# ATA6286 device description
Architecture: AVR8; Family: megaAVR
Registers are 8-bit, access not given, no defined reset value unless marked. A register's access mark holds for its fields unless they carry their own. Offsets are from the block's base; [hi:lo] are bit positions.

## LFRX
Instances: LFRX 0x00
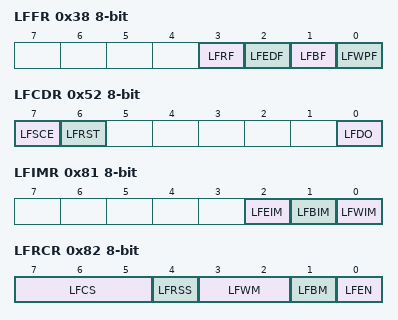
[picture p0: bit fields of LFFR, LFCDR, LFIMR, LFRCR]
0x38 LFFR — Low Frequency Flag Register
  [3] LFRF — LF receiver Rssi data Flag
  [2] LFEDF — LF receiver End of data Flag
  [1] LFBF — LF receiver data Buffer full Flag
  [0] LFWPF — LF receiver Wake-up Flag
0x50 LFRR bits used 6:0 — LF RSSI Data Register
0x52 LFCDR — LF receiver Control und Data Register
  [7] LFSCE — LF receiver RSSI Software Capture Enable Bit
  [6] LFRST — LF receiver Reset Bit
  [0] LFDO — LF receiver Data Output Bit
0x56 LFRB — Low Frequency Receive data Buffer
0x81 LFIMR — Low Frequency Interrupt Mask Register
  [2] LFEIM — LF receiver End of data Interrupt Mask bit
  [1] LFBIM — LF receiver data Buffer Interrupt Mask bit
  [0] LFWIM — LF receiver Wake-up Interrupt Mask bit
0x82 LFRCR — Low Frequency Receiver Control Register
  [7:5] LFCS — LF receiver Capacitor Select Bits
  [4] LFRSS — LF Receiver Sensitivity Select Bit
  [3:2] LFWM — LF receiver Wake-up Mode Bits
  [1] LFBM — LF receiver Burst Mode enable Bit
  [0] LFEN — LF receiver Enable Bit
0x83 LFHCR bits used 6:0 — LF Header Compare Register
0x84 LFIDC 16-bit — LF ID Compare Register
0x86 LFCAL 16-bit — LF Calibration Register Bytes

## EXTERNAL_INTERRUPT
Instances: EXTERNAL_INTERRUPT 0x00
0x37 PCIFR — Pin Change Interrupt Flag Register
  [2:0] PCIF — Pin Change Interrupt Flags
0x3D EIFR — External Interrupt Flag Register
  [1:0] INTF — External Interrupt Flags
0x43 PCICR — Pin Change Interrupt Control Register
  [2:0] PCIE — Pin Change Interrupt Enables
0x44 EIMSK — External Interrupt Mask Register
  [1:0] INT — External Interrupt Request 1 Enable
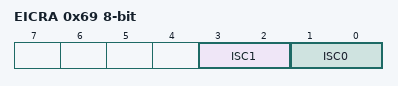
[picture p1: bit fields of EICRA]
0x69 EICRA — External Interrupt Control Register
  [3:2] ISC1 — External Interrupt Sense Control 1 Bits
  [1:0] ISC0 — External Interrupt Sense Control 0 Bits
0x6A PCMSK0 — Pin Change Mask Register 0
  [7:0] PCINT — Pin Change Enable Masks
0x6B PCMSK1 — Pin Change Mask Register 1
  [2:0] PCINT (bit 8 of the value upward) — Pin Change Enable Masks
0x6C PCMSK2 — Pin Change Mask Register 2
  [7:0] PCINT (bit 16 of the value upward) — Pin Change Enable Masks

## PORTB
Instances: PORTB 0x00
0x23 PINB — Port B Input Pins
0x24 DDRB — Port B Data Direction Register
0x25 PORTB — Port B Data Register

## PORTD
Instances: PORTD 0x00
0x29 PIND — Port D Input Pins
0x2A DDRD — Port D Data Direction Register
0x2B PORTD — Port D Data Register

## TIMER_COUNTER_1
Instances: TIMER_COUNTER_1 0x00
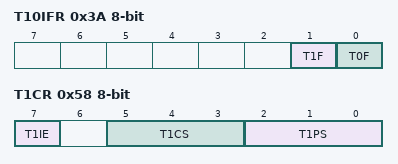
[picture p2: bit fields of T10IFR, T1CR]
0x3A T10IFR — Timer1/0 Interrupt Flag Register
  [1] T1F — Timer 1 Flag Bit
  [0] T0F — Timer 0 Flag Bit
0x58 T1CR — Timer 1 Control Register
  [7] T1IE — Timer 1 Interrupt Enable Bit
  [5:3] T1CS — Timer 1 Clock Select Bits
  [2:0] T1PS — Timer 1 Prescaler Select Bits

## TIMER_COUNTER_2
Instances: TIMER_COUNTER_2 0x00
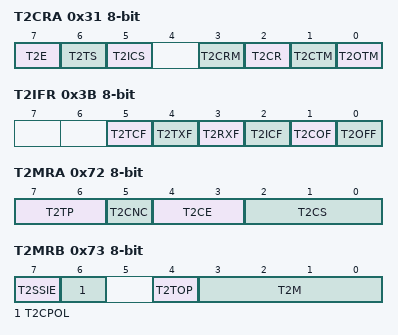
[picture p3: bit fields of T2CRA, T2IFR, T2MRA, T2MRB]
0x31 T2CRA — Timer 2 Control Register A
  [7] T2E — Timer 2 Enable Bit
  [6] T2TS — Timer 2 Toggle with Start Bit
  [5] T2ICS — Timer Input Capture Select Bit
  [3] T2CRM — Timer 2 Compare Reset Mask Bit
  [2] T2CR — Timer2 Counter Reset
  [1] T2CTM — Timer 2 Compare Toggle Mask Bit
  [0] T2OTM — Timer 2 Overflow Toggle Mask Bit
0x32 T2CRB — Timer 2 Control Register B
  [0] T2SCE — Timer 2 Software Capture Enable Bit
0x3B T2IFR — Timer2 Interrupt Flag Register
  [5] T2TCF — Timer2 SSI Transmit Complete Flag Bit
  [4] T2TXF — Timer2 SSI Transmit Flag Bit
  [3] T2RXF — Timer2 SSI Receive Flag Bit
  [2] T2ICF — Timer2 Input Capture Flag Bit
  [1] T2COF — Timer 2 Compare Flag Bit
  [0] T2OFF — Timer 2 Overflow Flag Bit
0x4F T2MDR — Timer 2 Modulator Data Register
0x6E T2ICRL — Timer 2 Input Capture Register Low Byte
0x6F T2ICR — Timer 2 Input Capture Register High Byte
0x70 T2COR 16-bit — Timer2 Compare Register Bytes
0x72 T2MRA — Timer 2 Mode Register A
  [7:6] T2TP — Timer 2 Top select Bits
  [5] T2CNC — Timer 2 Input Capture Noise Canceler Bit
  [4:3] T2CE — Timer 2 Capture Edge Select Bits
  [2:0] T2CS — Timer 2 Clock Select Bits
0x73 T2MRB — Timer 2 Mode Register B
  [7] T2SSIE — Timer 2 SSI Enable Bit
  [6] T2CPOL — Timer2 Clock Polarity for SSI shift clock
  [4] T2TOP — Timer 2 Toggle Output Preset Bit
  [3:0] T2M — Timer 2 Mode Bits
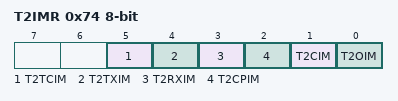
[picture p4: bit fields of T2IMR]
0x74 T2IMR — Timer 2 Interrupt Mask Register
  [5] T2TCIM — Timer2 SSI Transmit Complete Interrupt Mask Bit
  [4] T2TXIM — Timer2 SSI Transmit Interrupt Mask Bit
  [3] T2RXIM — Timer2 SSI Receive Interrupt Mask Bit
  [2] T2CPIM — Timer 2 Capture Interrupt Mask Bit
  [1] T2CIM — Timer 2 Compare Interrupt Mask Bit
  [0] T2OIM — Timer 2 Overflow Interrupt Mask Bit

## TIMER_COUNTER_3
Instances: TIMER_COUNTER_3 0x00
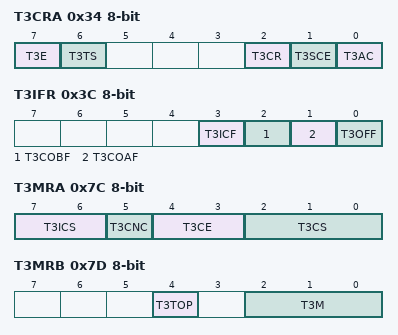
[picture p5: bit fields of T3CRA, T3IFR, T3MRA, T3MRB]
0x34 T3CRA — Timer 3 Control Register A
  [7] T3E — Timer 3 Enable Bit
  [6] T3TS — Timer 3 Toggle with Start Bit
  [2] T3CR — Timer3 Counter Reset
  [1] T3SCE — Timer 3 Software Capture Enable Bit
  [0] T3AC — Timer 3 Alternate Compare register sequence bit
0x3C T3IFR — Timer3 Interrupt Flag Register
  [3] T3ICF — Timer3 Input Capture Flag bit
  [2] T3COBF — Timer3 Compare B Flag bit
  [1] T3COAF — Timer3 Compare A Flag bit
  [0] T3OFF — Timer3 OverFlow Flag bit
0x76 T3ICR 16-bit — Timer3 Input Capture Register Bytes
0x78 T3CORA 16-bit — Timer3 COmpare Register A Bytes
0x7A T3CORB 16-bit — Timer3 COmpare Register B Bytes
0x7C T3MRA — Timer 3 Mode Register A
  [7:6] T3ICS — Timer 3 Input Capture Select Bits
  [5] T3CNC — Timer 3 input Capture Noise Canceler Bit
  [4:3] T3CE — Timer 3 Capture Edge select Bits
  [2:0] T3CS — Timer 3 Clock Select Bits
0x7D T3MRB — Timer 3 Mode Register B
  [4] T3TOP — Timer 3 Toggle Output Preset Bit
  [2:0] T3M — Timer 3 Mode Bits
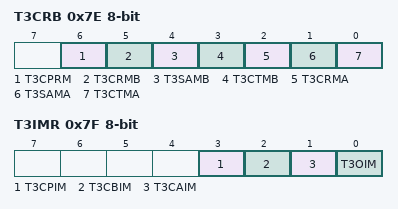
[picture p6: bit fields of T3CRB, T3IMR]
0x7E T3CRB — Timer 3 Control Register B
  [6] T3CPRM — Timer 3 CaPture Reset Mask bit
  [5] T3CRMB — Timer 3 Compare Reset Mask bit B
  [4] T3SAMB — Timer 3 Single Action Mask bit B
  [3] T3CTMB — Timer 3 Compare Toggle Mask bit B
  [2] T3CRMA — Timer 3 Compare Reset Mask bit A
  [1] T3SAMA — Timer 3 Single Action Mask bit A
  [0] T3CTMA — Timer 3 Compare Toggle Mask bit A
0x7F T3IMR — Timer3 Interrupt Mask Register
  [3] T3CPIM — Timer3 Capture Interrupt Mask bit
  [2] T3CBIM — Timer3 Compare B Interrupt Mask bit
  [1] T3CAIM — Timer3 Compare A Interrupt Mask bit
  [0] T3OIM — Timer3 Overflow Interrupt Mask bit

## WDT — Watchdog Timer
Instances: WDT 0x00
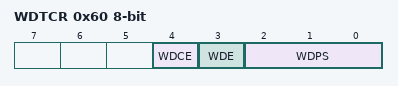
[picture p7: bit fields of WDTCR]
0x60 WDTCR — Watchdog Timer Control Register
  [4] WDCE — Watchdog Change Enable
  [3] WDE — Watch Dog Enable
  [2:0] WDPS — Watch Dog Timer Prescaler Select bits

## TIMER_COUNTER_0
Instances: TIMER_COUNTER_0 0x00
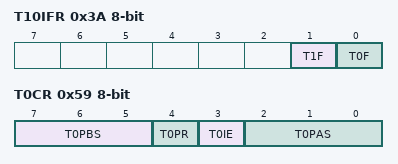
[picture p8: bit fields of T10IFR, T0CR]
0x3A T10IFR — Timer1/0 Interrupt Flag Register
  [1] T1F — Timer 1 Flag Bit
  [0] T0F — Timer 0 Flag Bit
0x59 T0CR — Timer 0 Control Register
  [7:5] T0PBS — Timer 0 Prescaler B Select Bits
  [4] T0PR — Timer 0 Prescaler Reset Bit
  [3] T0IE — Timer 0 Interrupt Enable Bit
  [2:0] T0PAS — Timer 0 Prescaler A Select Bits

## EEPROM
Instances: EEPROM 0x00
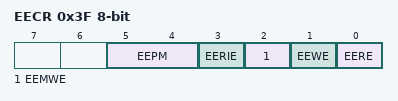
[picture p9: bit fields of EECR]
0x3F EECR — EEPROM Control Register
  [5:4] EEPM — EEPROM Programming Mode Bits
  [3] EERIE — EEPROM Ready Interrupt Enable
  [2] EEMWE — EEPROM Master Write Enable
  [1] EEWE — EEPROM Write Enable
  [0] EERE — EEPROM Read Enable
0x40 EEDR — EEPROM Data Register
0x41 EEAR 16-bit bits used 8:0 — EEPROM Address Register Bytes

## PORTC
Instances: PORTC 0x00
0x26 PINC bits used 2:0 — Port C Input Pins
0x27 DDRC bits used 2:0 — Port C Data Direction Register
0x28 PORTC bits used 2:0 — Port C Data Register
